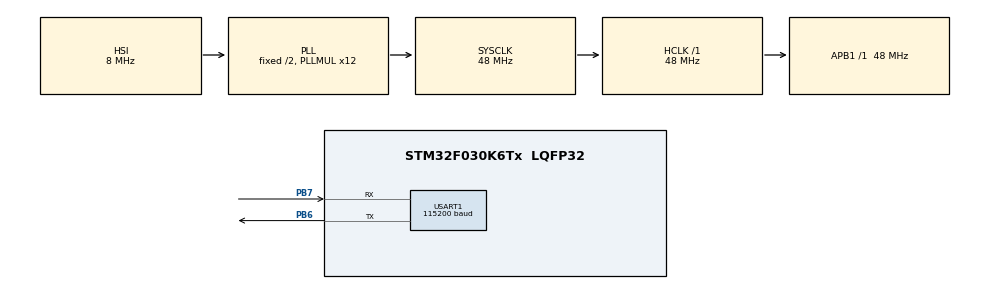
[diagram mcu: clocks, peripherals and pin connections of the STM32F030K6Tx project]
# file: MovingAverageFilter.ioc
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Mcu.Family=STM32F0
Mcu.Name=STM32F030K6Tx
Mcu.Package=LQFP32
PB6.Mode=Asynchronous
PB6.Signal=USART1_TX
PB7.Mode=Asynchronous
PB7.Signal=USART1_RX
ProjectManager.HeapSize=0x200
ProjectManager.StackSize=0x400
ProjectManager.TargetToolchain=MDK-ARM V5
RCC.AHBFreq_Value=48000000
RCC.APB1Freq_Value=48000000
RCC.APB1TimFreq_Value=48000000
RCC.HCLKFreq_Value=48000000
RCC.PLLMUL=RCC_PLL_MUL12
RCC.SYSCLKFreq_VALUE=48000000
RCC.SYSCLKSource=RCC_SYSCLKSOURCE_PLLCLK
USART1.BaudRate=115200
USART1.VirtualMode-Asynchronous=VM_ASYNC
board=custom

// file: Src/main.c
/* USER CODE BEGIN Header */
/**
 ******************************************************************************
 * ______  _                             ___  ___        _
 * | ___ \(_)                            |  \/  |       | |
 * | |_/ / _  _ __    __ _  _ __  _   _  | .  . |  __ _ | | __ ___  _ __
 * | ___ \| || '_ \  / _` || '__|| | | | | |\/| | / _` || |/ // _ \| '__|
 * | |_/ /| || | | || (_| || |   | |_| | | |  | || (_| ||   <|  __/| |
 * \____/ |_||_| |_| \__,_||_|    \__, | \_|  |_/ \__,_||_|\_\\___||_|
 *                                 __/ |
 *                                |___/
 *
 * Copyright (C) 2019 Binary Maker - All Rights Reserved
 *
 * This program and the accompanying materials are made available
 * under the terms described in the LICENSE file which accompanies
 * this distribution.
 * Written by Binary Maker <https://github.com/binarymaker>
 ******************************************************************************
 */
/* USER CODE END Header */

#include "main.h"

/* USER CODE BEGIN Includes */
#include "moving-average.h"
#include "stdio-port-stm32.h"
#include "utility.h"
/* USER CODE END Includes */

UART_HandleTypeDef huart1;

/* USER CODE BEGIN PV */
uint16_t signal;
uint16_t error_signal;
uint32_t last_print;

movingAverage_t avg_filter;
movingAverage_t avg_filter_2;
movingAverage_t avg_filter_3;
/* USER CODE END PV */

void SystemClock_Config(void);
static void MX_GPIO_Init(void);
static void MX_USART1_UART_Init(void);

int main(void)
{

  /* MCU Configuration--------------------------------------------------------*/

  /* Reset of all peripherals, Initializes the Flash interface and the Systick. */
  HAL_Init();

  /* Configure the system clock */
  SystemClock_Config();

  /* Initialize all configured peripherals */
  MX_GPIO_Init();
  MX_USART1_UART_Init();
  /* USER CODE BEGIN 2 */
  moving_average_create(&avg_filter, 10, 100);
  moving_average_create(&avg_filter_2, 30, 100);
  moving_average_create(&avg_filter_3, 50, 100);
  /* wait for 1 sample time */
  HAL_Delay(100);

  /* USER CODE END 2 */

  /* Infinite loop */
  /* USER CODE BEGIN WHILE */
  signal = 500;
  while (1)
  {
    /* signal source */
    if (HAL_GetTick() == 10000)
    {
      signal = 1000;
    }
    if (HAL_GetTick() == 20000)
    {
      signal = 500;
    }

    /* Random noise injected to input --------*/
    error_signal = signal + MAX(0, random(-20, 20));

    /* Filter --------------------------------*/
    moving_average_filter(&avg_filter, error_signal);
    moving_average_filter(&avg_filter_2, error_signal);
    moving_average_filter(&avg_filter_3, error_signal);

    if (HAL_GetTick() - last_print > 100)
    {
      /* print filter values -------------------*/
      printf("$%d %d %d %d;", error_signal, avg_filter.filtered,
             avg_filter_2.filtered, avg_filter_3.filtered);

      last_print = HAL_GetTick();
    }
    /* USER CODE END WHILE */

  }
}

void SystemClock_Config(void)
{
  RCC_OscInitTypeDef RCC_OscInitStruct = { 0 };
  RCC_ClkInitTypeDef RCC_ClkInitStruct = { 0 };
  RCC_PeriphCLKInitTypeDef PeriphClkInit = { 0 };

  /**Initializes the CPU, AHB and APB busses clocks
   */
  RCC_OscInitStruct.OscillatorType = RCC_OSCILLATORTYPE_HSI;
  RCC_OscInitStruct.HSIState = RCC_HSI_ON;
  RCC_OscInitStruct.HSICalibrationValue = RCC_HSICALIBRATION_DEFAULT;
  RCC_OscInitStruct.PLL.PLLState = RCC_PLL_ON;
  RCC_OscInitStruct.PLL.PLLSource = RCC_PLLSOURCE_HSI;
  RCC_OscInitStruct.PLL.PLLMUL = RCC_PLL_MUL12;
  RCC_OscInitStruct.PLL.PREDIV = RCC_PREDIV_DIV1;
  if (HAL_RCC_OscConfig(&RCC_OscInitStruct) != HAL_OK)
  {
    Error_Handler();
  }
  /**Initializes the CPU, AHB and APB busses clocks
   */
  RCC_ClkInitStruct.ClockType = RCC_CLOCKTYPE_HCLK | RCC_CLOCKTYPE_SYSCLK
                                | RCC_CLOCKTYPE_PCLK1;
  RCC_ClkInitStruct.SYSCLKSource = RCC_SYSCLKSOURCE_PLLCLK;
  RCC_ClkInitStruct.AHBCLKDivider = RCC_SYSCLK_DIV1;
  RCC_ClkInitStruct.APB1CLKDivider = RCC_HCLK_DIV1;

  if (HAL_RCC_ClockConfig(&RCC_ClkInitStruct, FLASH_LATENCY_1) != HAL_OK)
  {
    Error_Handler();
  }
  PeriphClkInit.PeriphClockSelection = RCC_PERIPHCLK_USART1;
  PeriphClkInit.Usart1ClockSelection = RCC_USART1CLKSOURCE_PCLK1;
  if (HAL_RCCEx_PeriphCLKConfig(&PeriphClkInit) != HAL_OK)
  {
    Error_Handler();
  }
}

static void MX_USART1_UART_Init(void)
{

  huart1.Instance = USART1;
  huart1.Init.BaudRate = 115200;
  huart1.Init.WordLength = UART_WORDLENGTH_8B;
  huart1.Init.StopBits = UART_STOPBITS_1;
  huart1.Init.Parity = UART_PARITY_NONE;
  huart1.Init.Mode = UART_MODE_TX_RX;
  huart1.Init.HwFlowCtl = UART_HWCONTROL_NONE;
  huart1.Init.OverSampling = UART_OVERSAMPLING_16;
  huart1.Init.OneBitSampling = UART_ONE_BIT_SAMPLE_DISABLE;
  huart1.AdvancedInit.AdvFeatureInit = UART_ADVFEATURE_NO_INIT;
  if (HAL_UART_Init(&huart1) != HAL_OK)
  {
    Error_Handler();
  }
}

static void MX_GPIO_Init(void)
{
  /* GPIO Ports Clock Enable */
  __HAL_RCC_GPIOB_CLK_ENABLE();
}

void Error_Handler(void)
{
}

/************************ (C) COPYRIGHT STMicroelectronics *****END OF FILE****/
